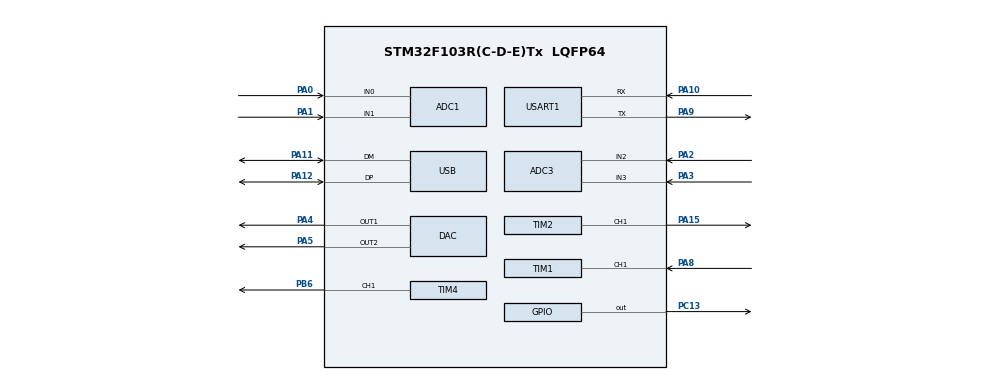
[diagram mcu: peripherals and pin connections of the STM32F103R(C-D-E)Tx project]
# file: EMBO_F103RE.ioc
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ADC1.AWD1ITMode=ENABLE
ADC1.Channel-6\#ChannelRegularConversion=ADC_CHANNEL_VREFINT
ADC1.Channel-7\#ChannelRegularConversion=ADC_CHANNEL_0
ADC1.Channel-8\#ChannelRegularConversion=ADC_CHANNEL_1
ADC1.EnableAnalogWatchDog=true
ADC1.ExternalTrigConv=ADC_EXTERNALTRIGCONV_T8_TRGO
ADC1.NbrOfConversion=3
ADC1.NbrOfConversionFlag=1
ADC1.Rank-6\#ChannelRegularConversion=1
ADC1.Rank-7\#ChannelRegularConversion=2
ADC1.Rank-8\#ChannelRegularConversion=3
ADC1.SamplingTime-6\#ChannelRegularConversion=ADC_SAMPLETIME_1CYCLE_5
ADC1.SamplingTime-7\#ChannelRegularConversion=ADC_SAMPLETIME_1CYCLE_5
ADC1.SamplingTime-8\#ChannelRegularConversion=ADC_SAMPLETIME_1CYCLE_5
ADC1.master=1
ADC3.AWD1ITMode=ENABLE
ADC3.Channel-0\#ChannelRegularConversion=ADC_CHANNEL_2
ADC3.Channel-1\#ChannelRegularConversion=ADC_CHANNEL_2
ADC3.EnableAnalogWatchDog=true
ADC3.ExternalTrigConv=ADC_EXTERNALTRIGCONV_T8_TRGO
ADC3.NbrOfConversion=2
ADC3.NbrOfConversionFlag=1
ADC3.Rank-0\#ChannelRegularConversion=1
ADC3.Rank-1\#ChannelRegularConversion=2
ADC3.SamplingTime-0\#ChannelRegularConversion=ADC_SAMPLETIME_1CYCLE_5
ADC3.SamplingTime-1\#ChannelRegularConversion=ADC_SAMPLETIME_1CYCLE_5
ADC3.WatchdogChannel=ADC_CHANNEL_2
DAC.DAC_Trigger=DAC_TRIGGER_T6_TRGO
DAC.DAC_Trigger2=DAC_TRIGGER_T7_TRGO
Dma.ADC1.2.Direction=DMA_PERIPH_TO_MEMORY
Dma.ADC1.2.Instance=DMA1_Channel1
Dma.ADC1.2.MemDataAlignment=DMA_MDATAALIGN_HALFWORD
Dma.ADC1.2.MemInc=DMA_MINC_ENABLE
Dma.ADC1.2.Mode=DMA_CIRCULAR
Dma.ADC1.2.PeriphDataAlignment=DMA_PDATAALIGN_HALFWORD
Dma.ADC1.2.PeriphInc=DMA_PINC_DISABLE
Dma.ADC1.2.Priority=DMA_PRIORITY_VERY_HIGH
Dma.ADC3.5.Direction=DMA_PERIPH_TO_MEMORY
Dma.ADC3.5.Instance=DMA2_Channel5
Dma.ADC3.5.MemDataAlignment=DMA_MDATAALIGN_HALFWORD
Dma.ADC3.5.MemInc=DMA_MINC_ENABLE
Dma.ADC3.5.Mode=DMA_CIRCULAR
Dma.ADC3.5.PeriphDataAlignment=DMA_PDATAALIGN_HALFWORD
Dma.ADC3.5.PeriphInc=DMA_PINC_DISABLE
Dma.ADC3.5.Priority=DMA_PRIORITY_VERY_HIGH
Dma.DAC_CH1.3.Direction=DMA_MEMORY_TO_PERIPH
Dma.DAC_CH1.3.Instance=DMA2_Channel3
Dma.DAC_CH1.3.MemDataAlignment=DMA_MDATAALIGN_WORD
Dma.DAC_CH1.3.MemInc=DMA_MINC_ENABLE
Dma.DAC_CH1.3.Mode=DMA_CIRCULAR
Dma.DAC_CH1.3.PeriphDataAlignment=DMA_PDATAALIGN_WORD
Dma.DAC_CH1.3.PeriphInc=DMA_PINC_DISABLE
Dma.DAC_CH1.3.Priority=DMA_PRIORITY_MEDIUM
Dma.DAC_CH2.4.Direction=DMA_MEMORY_TO_PERIPH
Dma.DAC_CH2.4.Instance=DMA2_Channel4
Dma.DAC_CH2.4.MemDataAlignment=DMA_MDATAALIGN_WORD
Dma.DAC_CH2.4.MemInc=DMA_MINC_ENABLE
Dma.DAC_CH2.4.Mode=DMA_CIRCULAR
Dma.DAC_CH2.4.PeriphDataAlignment=DMA_PDATAALIGN_WORD
Dma.DAC_CH2.4.PeriphInc=DMA_PINC_DISABLE
Dma.DAC_CH2.4.Priority=DMA_PRIORITY_MEDIUM
Dma.Request0=TIM1_CH1
Dma.Request1=TIM1_CH2
Dma.Request2=ADC1
Dma.Request3=DAC_CH1
Dma.Request4=DAC_CH2
Dma.Request5=ADC3
Dma.Request6=TIM8_CH3/UP
Dma.TIM1_CH1.0.Direction=DMA_PERIPH_TO_MEMORY
Dma.TIM1_CH1.0.Instance=DMA1_Channel2
Dma.TIM1_CH1.0.MemDataAlignment=DMA_MDATAALIGN_HALFWORD
Dma.TIM1_CH1.0.MemInc=DMA_MINC_ENABLE
Dma.TIM1_CH1.0.Mode=DMA_NORMAL
Dma.TIM1_CH1.0.PeriphDataAlignment=DMA_PDATAALIGN_HALFWORD
Dma.TIM1_CH1.0.PeriphInc=DMA_PINC_DISABLE
Dma.TIM1_CH1.0.Priority=DMA_PRIORITY_HIGH
Dma.TIM1_CH2.1.Direction=DMA_PERIPH_TO_MEMORY
Dma.TIM1_CH2.1.Instance=DMA1_Channel3
Dma.TIM1_CH2.1.MemDataAlignment=DMA_MDATAALIGN_HALFWORD
Dma.TIM1_CH2.1.MemInc=DMA_MINC_ENABLE
Dma.TIM1_CH2.1.Mode=DMA_NORMAL
Dma.TIM1_CH2.1.PeriphDataAlignment=DMA_PDATAALIGN_HALFWORD
Dma.TIM1_CH2.1.PeriphInc=DMA_PINC_DISABLE
Dma.TIM1_CH2.1.Priority=DMA_PRIORITY_HIGH
Dma.TIM8_CH3/UP.6.Direction=DMA_PERIPH_TO_MEMORY
Dma.TIM8_CH3/UP.6.Instance=DMA2_Channel1
Dma.TIM8_CH3/UP.6.MemDataAlignment=DMA_MDATAALIGN_BYTE
Dma.TIM8_CH3/UP.6.MemInc=DMA_MINC_ENABLE
Dma.TIM8_CH3/UP.6.Mode=DMA_CIRCULAR
Dma.TIM8_CH3/UP.6.PeriphDataAlignment=DMA_PDATAALIGN_BYTE
Dma.TIM8_CH3/UP.6.PeriphInc=DMA_PINC_DISABLE
Dma.TIM8_CH3/UP.6.Priority=DMA_PRIORITY_VERY_HIGH
Mcu.Family=STM32F1
Mcu.Name=STM32F103R(C-D-E)Tx
Mcu.Package=LQFP64
NVIC.PriorityGroup=NVIC_PRIORITYGROUP_4
NVIC.USB_LP_CAN1_RX0_IRQn=true\:7\:0\:true\:false\:true\:false\:true
PA0-WKUP.Signal=ADCx_IN0
PA1.Signal=ADCx_IN1
PA10.Mode=Asynchronous
PA10.Signal=USART1_RX
PA11.Mode=Device
PA11.Signal=USB_DM
PA12.Mode=Device
PA12.Signal=USB_DP
PA13.Mode=Trace_Asynchronous_SW
PA13.Signal=SYS_JTMS-SWDIO
PA14.Mode=Trace_Asynchronous_SW
PA14.Signal=SYS_JTCK-SWCLK
PA15.Signal=S_TIM2_CH1_ETR
PA2.Signal=ADCx_IN2
PA3.Signal=ADCx_IN3
PA4.Signal=COMP_DAC1_group
PA5.Signal=COMP_DAC2_group
PA8.Signal=S_TIM1_CH1
PA9.Mode=Asynchronous
PA9.Signal=USART1_TX
PB3.Mode=Trace_Asynchronous_SW
PB3.Signal=SYS_JTDO-TRACESWO
PB6.Signal=S_TIM4_CH1
PC13-TAMPER-RTC.PinState=GPIO_PIN_SET
PC13-TAMPER-RTC.Signal=GPIO_Output
PD0-OSC_IN.Mode=HSE-External-Oscillator
PD0-OSC_IN.Signal=RCC_OSC_IN
PD1-OSC_OUT.Mode=HSE-External-Oscillator
PD1-OSC_OUT.Signal=RCC_OSC_OUT
ProjectManager.HeapSize=0x0
ProjectManager.StackSize=0x400
ProjectManager.TargetToolchain=STM32CubeIDE
RCC.ADCPresc=RCC_ADCPCLK2_DIV6
RCC.AHBFreq_Value=72000000
RCC.APB1CLKDivider=RCC_HCLK_DIV2
RCC.APB1Freq_Value=36000000
RCC.APB1TimFreq_Value=72000000
RCC.APB2Freq_Value=72000000
RCC.APB2TimFreq_Value=72000000
RCC.HCLKFreq_Value=72000000
RCC.PLLMUL=RCC_PLL_MUL9
RCC.SYSCLKFreq_VALUE=72000000
RCC.SYSCLKSource=RCC_SYSCLKSOURCE_PLLCLK
RCC.USBFreq_Value=48000000
RCC.USBPrescaler=RCC_USBCLKSOURCE_PLL_DIV1_5
SH.ADCx_IN0.0=ADC1_IN0,IN0
SH.ADCx_IN1.0=ADC1_IN1,IN1
SH.ADCx_IN2.0=ADC3_IN2,IN2
SH.ADCx_IN3.0=ADC3_IN3,IN3
SH.COMP_DAC1_group.0=DAC_OUT1,DAC_OUT1
SH.COMP_DAC2_group.0=DAC_OUT2,DAC_OUT2
SH.S_TIM1_CH1.0=TIM1_CH1,Input_Capture1_from_TI1
SH.S_TIM1_CH1.1=TIM1_CH1,Input_Capture2_from_TI1
SH.S_TIM2_CH1_ETR.0=TIM2_CH1,PWM Generation1 CH1
SH.S_TIM4_CH1.0=TIM4_CH1,PWM Generation1 CH1
TIM1.Channel-Input_Capture1_from_TI1=TIM_CHANNEL_1
TIM1.Channel-Input_Capture2_from_TI1=TIM_CHANNEL_2
TIM1.Channel-Output\ Compare3\ No\ Output=TIM_CHANNEL_3
TIM2.Channel-PWM\ Generation1\ CH1=TIM_CHANNEL_1
TIM2.OCFastMode_PWM-PWM\ Generation1\ CH1=TIM_OCFAST_ENABLE
TIM2.Period=1000
TIM2.TIM_MasterOutputTrigger=TIM_TRGO_ENABLE
TIM2.TIM_MasterSlaveMode=TIM_MASTERSLAVEMODE_ENABLE
TIM4.AutoReloadPreload=TIM_AUTORELOAD_PRELOAD_ENABLE
TIM4.Channel-PWM\ Generation1\ CH1=TIM_CHANNEL_1
TIM4.OCFastMode_PWM-PWM\ Generation1\ CH1=TIM_OCFAST_ENABLE
TIM4.Period=72
TIM4.Prescaler=1000
TIM4.TIM_MasterOutputTrigger=TIM_TRGO_UPDATE
TIM6.TIM_MasterOutputTrigger=TIM_TRGO_UPDATE
TIM7.TIM_MasterOutputTrigger=TIM_TRGO_UPDATE
TIM8.Channel-Output\ Compare3\ No\ Output=TIM_CHANNEL_3
TIM8.TIM_MasterOutputTrigger=TIM_TRGO_UPDATE
USART1.VirtualMode=VM_ASYNC
USB_DEVICE.CLASS_NAME_FS=CDC
USB_DEVICE.MANUFACTURER_STRING=CTU/Jakub Parez
USB_DEVICE.PRODUCT_STRING_CDC_FS=EMBO
USB_DEVICE.VirtualMode=Cdc
USB_DEVICE.VirtualModeFS=Cdc_FS
VP_ADC1_Vref_Input.Mode=IN-Vrefint
VP_TIM1_VS_ClockSourceINT.Mode=Internal
VP_TIM1_VS_no_output3.Mode=Output Compare3 No Output
VP_TIM2_VS_ClockSourceINT.Mode=Internal
VP_TIM4_VS_ClockSourceINT.Mode=Internal
VP_TIM4_VS_ClockSourceITR.Mode=TriggerSource_ITR1
VP_TIM4_VS_ControllerModeTrigger.Mode=Trigger Mode
VP_TIM6_VS_ClockSourceINT.Mode=Enable_Timer
VP_TIM7_VS_ClockSourceINT.Mode=Enable_Timer
VP_TIM8_VS_ClockSourceINT.Mode=Internal
VP_TIM8_VS_no_output3.Mode=Output Compare3 No Output
VP_USB_DEVICE_VS_USB_DEVICE_CDC_FS.Mode=CDC_FS
board=custom

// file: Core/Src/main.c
/* USER CODE BEGIN Header */
/**
  ******************************************************************************
  * @file           : main.c
  * @brief          : Main program body
  ******************************************************************************
  * @attention
  *
  * <h2><center>&copy; Copyright (c) 2021 STMicroelectronics.
  * All rights reserved.</center></h2>
  *
  * This software component is licensed by ST under BSD 3-Clause license,
  * the "License"; You may not use this file except in compliance with the
  * License. You may obtain a copy of the License at:
  *                        opensource.org/licenses/BSD-3-Clause
  *
  ******************************************************************************
  */
/* USER CODE END Header */
#include "main.h"
#include "usb_device.h"

/* USER CODE BEGIN Includes */
#include "app.h"
/* USER CODE END Includes */

void SystemClock_Config(void);
static void MX_GPIO_Init(void);
static void MX_DMA_Init(void);
static void MX_TIM1_Init(void);
static void MX_USART1_UART_Init(void);
static void MX_ADC1_Init(void);
static void MX_DAC_Init(void);
static void MX_TIM2_Init(void);
static void MX_TIM4_Init(void);
static void MX_TIM6_Init(void);
static void MX_TIM7_Init(void);
static void MX_ADC3_Init(void);
static void MX_TIM8_Init(void);

int main(void)
{
  __disable_irq();

  /* MCU Configuration--------------------------------------------------------*/

  /* Reset of all peripherals, Initializes the Flash interface and the Systick. */
  HAL_Init();

  /* Configure the system clock */
  SystemClock_Config();

  /* Initialize all configured peripherals */
  MX_GPIO_Init();
  MX_DMA_Init();
  MX_TIM1_Init();
  MX_USART1_UART_Init();
  MX_ADC1_Init();
  MX_DAC_Init();
  MX_TIM2_Init();
  MX_TIM4_Init();
  MX_TIM6_Init();
  MX_USB_DEVICE_Init();
  MX_TIM7_Init();
  MX_ADC3_Init();
  MX_TIM8_Init();

  /* Infinite loop */
  /* USER CODE BEGIN WHILE */
  app_main();
    /* USER CODE END WHILE */

}

void SystemClock_Config(void)
{
  LL_FLASH_SetLatency(LL_FLASH_LATENCY_2);
  while(LL_FLASH_GetLatency()!= LL_FLASH_LATENCY_2)
  {
  }
  LL_RCC_HSE_Enable();

   /* Wait till HSE is ready */
  while(LL_RCC_HSE_IsReady() != 1)
  {

  }
  LL_RCC_PLL_ConfigDomain_SYS(LL_RCC_PLLSOURCE_HSE_DIV_1, LL_RCC_PLL_MUL_9);
  LL_RCC_PLL_Enable();

   /* Wait till PLL is ready */
  while(LL_RCC_PLL_IsReady() != 1)
  {

  }
  LL_RCC_SetAHBPrescaler(LL_RCC_SYSCLK_DIV_1);
  LL_RCC_SetAPB1Prescaler(LL_RCC_APB1_DIV_2);
  LL_RCC_SetAPB2Prescaler(LL_RCC_APB2_DIV_1);
  LL_RCC_SetSysClkSource(LL_RCC_SYS_CLKSOURCE_PLL);

   /* Wait till System clock is ready */
  while(LL_RCC_GetSysClkSource() != LL_RCC_SYS_CLKSOURCE_STATUS_PLL)
  {

  }
  LL_SetSystemCoreClock(72000000);

   /* Update the time base */
  if (HAL_InitTick (TICK_INT_PRIORITY) != HAL_OK)
  {
    Error_Handler();
  }
  LL_RCC_SetADCClockSource(LL_RCC_ADC_CLKSRC_PCLK2_DIV_6);
  LL_RCC_SetUSBClockSource(LL_RCC_USB_CLKSOURCE_PLL_DIV_1_5);
}

static void MX_ADC1_Init(void)
{

  LL_ADC_InitTypeDef ADC_InitStruct = {0};
  LL_ADC_CommonInitTypeDef ADC_CommonInitStruct = {0};
  LL_ADC_REG_InitTypeDef ADC_REG_InitStruct = {0};

  LL_GPIO_InitTypeDef GPIO_InitStruct = {0};

  /* Peripheral clock enable */
  LL_APB2_GRP1_EnableClock(LL_APB2_GRP1_PERIPH_ADC1);

  LL_APB2_GRP1_EnableClock(LL_APB2_GRP1_PERIPH_GPIOA);
  /**ADC1 GPIO Configuration
  PA0-WKUP   ------> ADC1_IN0
  PA1   ------> ADC1_IN1
  */
  GPIO_InitStruct.Pin = LL_GPIO_PIN_0|LL_GPIO_PIN_1;
  GPIO_InitStruct.Mode = LL_GPIO_MODE_ANALOG;
  LL_GPIO_Init(GPIOA, &GPIO_InitStruct);

  /* ADC1 DMA Init */

  /* ADC1 Init */
  LL_DMA_SetDataTransferDirection(DMA1, LL_DMA_CHANNEL_1, LL_DMA_DIRECTION_PERIPH_TO_MEMORY);

  LL_DMA_SetChannelPriorityLevel(DMA1, LL_DMA_CHANNEL_1, LL_DMA_PRIORITY_VERYHIGH);

  LL_DMA_SetMode(DMA1, LL_DMA_CHANNEL_1, LL_DMA_MODE_CIRCULAR);

  LL_DMA_SetPeriphIncMode(DMA1, LL_DMA_CHANNEL_1, LL_DMA_PERIPH_NOINCREMENT);

  LL_DMA_SetMemoryIncMode(DMA1, LL_DMA_CHANNEL_1, LL_DMA_MEMORY_INCREMENT);

  LL_DMA_SetPeriphSize(DMA1, LL_DMA_CHANNEL_1, LL_DMA_PDATAALIGN_HALFWORD);

  LL_DMA_SetMemorySize(DMA1, LL_DMA_CHANNEL_1, LL_DMA_MDATAALIGN_HALFWORD);

  /** Common config
  */
  ADC_InitStruct.DataAlignment = LL_ADC_DATA_ALIGN_RIGHT;
  ADC_InitStruct.SequencersScanMode = LL_ADC_SEQ_SCAN_ENABLE;
  LL_ADC_Init(ADC1, &ADC_InitStruct);
  ADC_CommonInitStruct.Multimode = LL_ADC_MULTI_INDEPENDENT;
  LL_ADC_CommonInit(__LL_ADC_COMMON_INSTANCE(ADC1), &ADC_CommonInitStruct);
  ADC_REG_InitStruct.TriggerSource = LL_ADC_REG_TRIG_EXT_TIM8_TRGO;
  ADC_REG_InitStruct.SequencerLength = LL_ADC_REG_SEQ_SCAN_ENABLE_3RANKS;
  ADC_REG_InitStruct.SequencerDiscont = LL_ADC_REG_SEQ_DISCONT_DISABLE;
  ADC_REG_InitStruct.ContinuousMode = LL_ADC_REG_CONV_SINGLE;
  ADC_REG_InitStruct.DMATransfer = LL_ADC_REG_DMA_TRANSFER_UNLIMITED;
  LL_ADC_REG_Init(ADC1, &ADC_REG_InitStruct);
  /** Configure Analog WatchDog
  */
  LL_ADC_SetAnalogWDMonitChannels(ADC1, LL_ADC_AWD_CHANNEL_0_REG);
  LL_ADC_SetAnalogWDThresholds(ADC1, LL_ADC_AWD_THRESHOLD_HIGH, 0);
  LL_ADC_SetAnalogWDThresholds(ADC1, LL_ADC_AWD_THRESHOLD_LOW, 0);
  LL_ADC_EnableIT_AWD1(ADC1);
  /** Configure Regular Channel
  */
  LL_ADC_REG_SetSequencerRanks(ADC1, LL_ADC_REG_RANK_1, LL_ADC_CHANNEL_VREFINT);
  LL_ADC_SetChannelSamplingTime(ADC1, LL_ADC_CHANNEL_VREFINT, LL_ADC_SAMPLINGTIME_1CYCLE_5);
  LL_ADC_SetCommonPathInternalCh(__LL_ADC_COMMON_INSTANCE(ADC1), LL_ADC_PATH_INTERNAL_VREFINT);
  /** Configure Regular Channel
  */
  LL_ADC_REG_SetSequencerRanks(ADC1, LL_ADC_REG_RANK_2, LL_ADC_CHANNEL_0);
  LL_ADC_SetChannelSamplingTime(ADC1, LL_ADC_CHANNEL_0, LL_ADC_SAMPLINGTIME_1CYCLE_5);
  /** Configure Regular Channel
  */
  LL_ADC_REG_SetSequencerRanks(ADC1, LL_ADC_REG_RANK_3, LL_ADC_CHANNEL_1);
  LL_ADC_SetChannelSamplingTime(ADC1, LL_ADC_CHANNEL_1, LL_ADC_SAMPLINGTIME_1CYCLE_5);

}

static void MX_ADC3_Init(void)
{

  /* USER CODE BEGIN ADC3_Init 0 */
  LL_ADC_REG_InitTypeDef ADC_REG_InitStruct = {0};
  /* USER CODE END ADC3_Init 0 */

  LL_ADC_InitTypeDef ADC_InitStruct = {0};

  LL_GPIO_InitTypeDef GPIO_InitStruct = {0};

  /* Peripheral clock enable */
  LL_APB2_GRP1_EnableClock(LL_APB2_GRP1_PERIPH_ADC3);

  LL_APB2_GRP1_EnableClock(LL_APB2_GRP1_PERIPH_GPIOA);
  /**ADC3 GPIO Configuration
  PA2   ------> ADC3_IN2
  PA3   ------> ADC3_IN3
  */
  GPIO_InitStruct.Pin = LL_GPIO_PIN_2|LL_GPIO_PIN_3;
  GPIO_InitStruct.Mode = LL_GPIO_MODE_ANALOG;
  LL_GPIO_Init(GPIOA, &GPIO_InitStruct);

  /* ADC3 DMA Init */

  /* ADC3 Init */
  LL_DMA_SetDataTransferDirection(DMA2, LL_DMA_CHANNEL_5, LL_DMA_DIRECTION_PERIPH_TO_MEMORY);

  LL_DMA_SetChannelPriorityLevel(DMA2, LL_DMA_CHANNEL_5, LL_DMA_PRIORITY_VERYHIGH);

  LL_DMA_SetMode(DMA2, LL_DMA_CHANNEL_5, LL_DMA_MODE_CIRCULAR);

  LL_DMA_SetPeriphIncMode(DMA2, LL_DMA_CHANNEL_5, LL_DMA_PERIPH_NOINCREMENT);

  LL_DMA_SetMemoryIncMode(DMA2, LL_DMA_CHANNEL_5, LL_DMA_MEMORY_INCREMENT);

  LL_DMA_SetPeriphSize(DMA2, LL_DMA_CHANNEL_5, LL_DMA_PDATAALIGN_HALFWORD);

  LL_DMA_SetMemorySize(DMA2, LL_DMA_CHANNEL_5, LL_DMA_MDATAALIGN_HALFWORD);

  /** Common config
  */
  ADC_InitStruct.DataAlignment = LL_ADC_DATA_ALIGN_RIGHT;
  ADC_InitStruct.SequencersScanMode = LL_ADC_SEQ_SCAN_ENABLE;
  LL_ADC_Init(ADC3, &ADC_InitStruct);
  /** Configure Analog WatchDog
  */
  LL_ADC_SetAnalogWDMonitChannels(ADC3, LL_ADC_AWD_CHANNEL_2_REG);
  LL_ADC_SetAnalogWDThresholds(ADC3, LL_ADC_AWD_THRESHOLD_HIGH, 0);
  LL_ADC_SetAnalogWDThresholds(ADC3, LL_ADC_AWD_THRESHOLD_LOW, 0);
  LL_ADC_EnableIT_AWD1(ADC3);
  /** Configure Regular Channel
  */
  LL_ADC_REG_SetSequencerRanks(ADC3, LL_ADC_REG_RANK_1, LL_ADC_CHANNEL_2);
  LL_ADC_SetChannelSamplingTime(ADC3, LL_ADC_CHANNEL_2, LL_ADC_SAMPLINGTIME_1CYCLE_5);
  /** Configure Regular Channel
  */
  LL_ADC_REG_SetSequencerRanks(ADC3, LL_ADC_REG_RANK_2, LL_ADC_CHANNEL_2);
  LL_ADC_SetChannelSamplingTime(ADC3, LL_ADC_CHANNEL_2, LL_ADC_SAMPLINGTIME_1CYCLE_5);
  /* USER CODE BEGIN ADC3_Init 2 */

  ADC_REG_InitStruct.TriggerSource = LL_ADC_REG_TRIG_EXT_TIM8_TRGO_ADC3;
  ADC_REG_InitStruct.SequencerLength = LL_ADC_REG_SEQ_SCAN_ENABLE_2RANKS;
  ADC_REG_InitStruct.SequencerDiscont = LL_ADC_REG_SEQ_DISCONT_DISABLE;
  ADC_REG_InitStruct.ContinuousMode = LL_ADC_REG_CONV_SINGLE;
  ADC_REG_InitStruct.DMATransfer = LL_ADC_REG_DMA_TRANSFER_UNLIMITED;
  LL_ADC_REG_Init(ADC3, &ADC_REG_InitStruct);

  /* USER CODE END ADC3_Init 2 */

}

static void MX_DAC_Init(void)
{

  LL_DAC_InitTypeDef DAC_InitStruct = {0};

  LL_GPIO_InitTypeDef GPIO_InitStruct = {0};

  /* Peripheral clock enable */
  LL_APB1_GRP1_EnableClock(LL_APB1_GRP1_PERIPH_DAC1);

  LL_APB2_GRP1_EnableClock(LL_APB2_GRP1_PERIPH_GPIOA);
  /**DAC GPIO Configuration
  PA4   ------> DAC_OUT1
  PA5   ------> DAC_OUT2
  */
  GPIO_InitStruct.Pin = LL_GPIO_PIN_4|LL_GPIO_PIN_5;
  GPIO_InitStruct.Mode = LL_GPIO_MODE_ANALOG;
  LL_GPIO_Init(GPIOA, &GPIO_InitStruct);

  /* DAC DMA Init */

  /* DAC_CH1 Init */
  LL_DMA_SetDataTransferDirection(DMA2, LL_DMA_CHANNEL_3, LL_DMA_DIRECTION_MEMORY_TO_PERIPH);

  LL_DMA_SetChannelPriorityLevel(DMA2, LL_DMA_CHANNEL_3, LL_DMA_PRIORITY_MEDIUM);

  LL_DMA_SetMode(DMA2, LL_DMA_CHANNEL_3, LL_DMA_MODE_CIRCULAR);

  LL_DMA_SetPeriphIncMode(DMA2, LL_DMA_CHANNEL_3, LL_DMA_PERIPH_NOINCREMENT);

  LL_DMA_SetMemoryIncMode(DMA2, LL_DMA_CHANNEL_3, LL_DMA_MEMORY_INCREMENT);

  LL_DMA_SetPeriphSize(DMA2, LL_DMA_CHANNEL_3, LL_DMA_PDATAALIGN_WORD);

  LL_DMA_SetMemorySize(DMA2, LL_DMA_CHANNEL_3, LL_DMA_MDATAALIGN_WORD);

  /* DAC_CH2 Init */
  LL_DMA_SetDataTransferDirection(DMA2, LL_DMA_CHANNEL_4, LL_DMA_DIRECTION_MEMORY_TO_PERIPH);

  LL_DMA_SetChannelPriorityLevel(DMA2, LL_DMA_CHANNEL_4, LL_DMA_PRIORITY_MEDIUM);

  LL_DMA_SetMode(DMA2, LL_DMA_CHANNEL_4, LL_DMA_MODE_CIRCULAR);

  LL_DMA_SetPeriphIncMode(DMA2, LL_DMA_CHANNEL_4, LL_DMA_PERIPH_NOINCREMENT);

  LL_DMA_SetMemoryIncMode(DMA2, LL_DMA_CHANNEL_4, LL_DMA_MEMORY_INCREMENT);

  LL_DMA_SetPeriphSize(DMA2, LL_DMA_CHANNEL_4, LL_DMA_PDATAALIGN_WORD);

  LL_DMA_SetMemorySize(DMA2, LL_DMA_CHANNEL_4, LL_DMA_MDATAALIGN_WORD);

  /** DAC channel OUT1 config
  */
  DAC_InitStruct.TriggerSource = LL_DAC_TRIG_EXT_TIM6_TRGO;
  DAC_InitStruct.WaveAutoGeneration = LL_DAC_WAVE_AUTO_GENERATION_NONE;
  DAC_InitStruct.OutputBuffer = LL_DAC_OUTPUT_BUFFER_ENABLE;
  LL_DAC_Init(DAC, LL_DAC_CHANNEL_1, &DAC_InitStruct);
  LL_DAC_EnableTrigger(DAC, LL_DAC_CHANNEL_1);
  /** DAC channel OUT2 config
  */
  DAC_InitStruct.TriggerSource = LL_DAC_TRIG_EXT_TIM7_TRGO;
  LL_DAC_Init(DAC, LL_DAC_CHANNEL_2, &DAC_InitStruct);
  LL_DAC_EnableTrigger(DAC, LL_DAC_CHANNEL_2);

}

static void MX_TIM1_Init(void)
{

  LL_TIM_InitTypeDef TIM_InitStruct = {0};
  LL_TIM_OC_InitTypeDef TIM_OC_InitStruct = {0};
  LL_TIM_BDTR_InitTypeDef TIM_BDTRInitStruct = {0};

  LL_GPIO_InitTypeDef GPIO_InitStruct = {0};

  /* Peripheral clock enable */
  LL_APB2_GRP1_EnableClock(LL_APB2_GRP1_PERIPH_TIM1);

  LL_APB2_GRP1_EnableClock(LL_APB2_GRP1_PERIPH_GPIOA);
  /**TIM1 GPIO Configuration
  PA8   ------> TIM1_CH1
  */
  GPIO_InitStruct.Pin = LL_GPIO_PIN_8;
  GPIO_InitStruct.Mode = LL_GPIO_MODE_FLOATING;
  LL_GPIO_Init(GPIOA, &GPIO_InitStruct);

  /* TIM1 DMA Init */

  /* TIM1_CH1 Init */
  LL_DMA_SetDataTransferDirection(DMA1, LL_DMA_CHANNEL_2, LL_DMA_DIRECTION_PERIPH_TO_MEMORY);

  LL_DMA_SetChannelPriorityLevel(DMA1, LL_DMA_CHANNEL_2, LL_DMA_PRIORITY_HIGH);

  LL_DMA_SetMode(DMA1, LL_DMA_CHANNEL_2, LL_DMA_MODE_NORMAL);

  LL_DMA_SetPeriphIncMode(DMA1, LL_DMA_CHANNEL_2, LL_DMA_PERIPH_NOINCREMENT);

  LL_DMA_SetMemoryIncMode(DMA1, LL_DMA_CHANNEL_2, LL_DMA_MEMORY_INCREMENT);

  LL_DMA_SetPeriphSize(DMA1, LL_DMA_CHANNEL_2, LL_DMA_PDATAALIGN_HALFWORD);

  LL_DMA_SetMemorySize(DMA1, LL_DMA_CHANNEL_2, LL_DMA_MDATAALIGN_HALFWORD);

  /* TIM1_CH2 Init */
  LL_DMA_SetDataTransferDirection(DMA1, LL_DMA_CHANNEL_3, LL_DMA_DIRECTION_PERIPH_TO_MEMORY);

  LL_DMA_SetChannelPriorityLevel(DMA1, LL_DMA_CHANNEL_3, LL_DMA_PRIORITY_HIGH);

  LL_DMA_SetMode(DMA1, LL_DMA_CHANNEL_3, LL_DMA_MODE_NORMAL);

  LL_DMA_SetPeriphIncMode(DMA1, LL_DMA_CHANNEL_3, LL_DMA_PERIPH_NOINCREMENT);

  LL_DMA_SetMemoryIncMode(DMA1, LL_DMA_CHANNEL_3, LL_DMA_MEMORY_INCREMENT);

  LL_DMA_SetPeriphSize(DMA1, LL_DMA_CHANNEL_3, LL_DMA_PDATAALIGN_HALFWORD);

  LL_DMA_SetMemorySize(DMA1, LL_DMA_CHANNEL_3, LL_DMA_MDATAALIGN_HALFWORD);

  TIM_InitStruct.Prescaler = 0;
  TIM_InitStruct.CounterMode = LL_TIM_COUNTERMODE_UP;
  TIM_InitStruct.Autoreload = 65535;
  TIM_InitStruct.ClockDivision = LL_TIM_CLOCKDIVISION_DIV1;
  TIM_InitStruct.RepetitionCounter = 0;
  LL_TIM_Init(TIM1, &TIM_InitStruct);
  LL_TIM_DisableARRPreload(TIM1);
  LL_TIM_SetClockSource(TIM1, LL_TIM_CLOCKSOURCE_INTERNAL);
  TIM_OC_InitStruct.OCMode = LL_TIM_OCMODE_FROZEN;
  TIM_OC_InitStruct.OCState = LL_TIM_OCSTATE_DISABLE;
  TIM_OC_InitStruct.OCNState = LL_TIM_OCSTATE_DISABLE;
  TIM_OC_InitStruct.CompareValue = 0;
  TIM_OC_InitStruct.OCPolarity = LL_TIM_OCPOLARITY_HIGH;
  TIM_OC_InitStruct.OCNPolarity = LL_TIM_OCPOLARITY_HIGH;
  TIM_OC_InitStruct.OCIdleState = LL_TIM_OCIDLESTATE_LOW;
  TIM_OC_InitStruct.OCNIdleState = LL_TIM_OCIDLESTATE_LOW;
  LL_TIM_OC_Init(TIM1, LL_TIM_CHANNEL_CH3, &TIM_OC_InitStruct);
  LL_TIM_OC_DisableFast(TIM1, LL_TIM_CHANNEL_CH3);
  LL_TIM_SetTriggerOutput(TIM1, LL_TIM_TRGO_RESET);
  LL_TIM_DisableMasterSlaveMode(TIM1);
  LL_TIM_IC_SetActiveInput(TIM1, LL_TIM_CHANNEL_CH1, LL_TIM_ACTIVEINPUT_DIRECTTI);
  LL_TIM_IC_SetPrescaler(TIM1, LL_TIM_CHANNEL_CH1, LL_TIM_ICPSC_DIV1);
  LL_TIM_IC_SetFilter(TIM1, LL_TIM_CHANNEL_CH1, LL_TIM_IC_FILTER_FDIV1);
  LL_TIM_IC_SetPolarity(TIM1, LL_TIM_CHANNEL_CH1, LL_TIM_IC_POLARITY_RISING);
  LL_TIM_IC_SetActiveInput(TIM1, LL_TIM_CHANNEL_CH2, LL_TIM_ACTIVEINPUT_INDIRECTTI);
  LL_TIM_IC_SetPrescaler(TIM1, LL_TIM_CHANNEL_CH2, LL_TIM_ICPSC_DIV1);
  LL_TIM_IC_SetFilter(TIM1, LL_TIM_CHANNEL_CH2, LL_TIM_IC_FILTER_FDIV1);
  LL_TIM_IC_SetPolarity(TIM1, LL_TIM_CHANNEL_CH2, LL_TIM_IC_POLARITY_RISING);
  TIM_BDTRInitStruct.OSSRState = LL_TIM_OSSR_DISABLE;
  TIM_BDTRInitStruct.OSSIState = LL_TIM_OSSI_DISABLE;
  TIM_BDTRInitStruct.LockLevel = LL_TIM_LOCKLEVEL_OFF;
  TIM_BDTRInitStruct.DeadTime = 0;
  TIM_BDTRInitStruct.BreakState = LL_TIM_BREAK_DISABLE;
  TIM_BDTRInitStruct.BreakPolarity = LL_TIM_BREAK_POLARITY_HIGH;
  TIM_BDTRInitStruct.AutomaticOutput = LL_TIM_AUTOMATICOUTPUT_DISABLE;
  LL_TIM_BDTR_Init(TIM1, &TIM_BDTRInitStruct);

}

static void MX_TIM2_Init(void)
{

  LL_TIM_InitTypeDef TIM_InitStruct = {0};
  LL_TIM_OC_InitTypeDef TIM_OC_InitStruct = {0};

  LL_GPIO_InitTypeDef GPIO_InitStruct = {0};

  /* Peripheral clock enable */
  LL_APB1_GRP1_EnableClock(LL_APB1_GRP1_PERIPH_TIM2);

  TIM_InitStruct.Prescaler = 0;
  TIM_InitStruct.CounterMode = LL_TIM_COUNTERMODE_UP;
  TIM_InitStruct.Autoreload = 1000;
  TIM_InitStruct.ClockDivision = LL_TIM_CLOCKDIVISION_DIV1;
  LL_TIM_Init(TIM2, &TIM_InitStruct);
  LL_TIM_DisableARRPreload(TIM2);
  LL_TIM_SetClockSource(TIM2, LL_TIM_CLOCKSOURCE_INTERNAL);
  LL_TIM_OC_EnablePreload(TIM2, LL_TIM_CHANNEL_CH1);
  TIM_OC_InitStruct.OCMode = LL_TIM_OCMODE_PWM1;
  TIM_OC_InitStruct.OCState = LL_TIM_OCSTATE_DISABLE;
  TIM_OC_InitStruct.OCNState = LL_TIM_OCSTATE_DISABLE;
  TIM_OC_InitStruct.CompareValue = 0;
  TIM_OC_InitStruct.OCPolarity = LL_TIM_OCPOLARITY_HIGH;
  LL_TIM_OC_Init(TIM2, LL_TIM_CHANNEL_CH1, &TIM_OC_InitStruct);
  LL_TIM_OC_EnableFast(TIM2, LL_TIM_CHANNEL_CH1);
  LL_TIM_SetTriggerOutput(TIM2, LL_TIM_TRGO_ENABLE);
  LL_TIM_EnableMasterSlaveMode(TIM2);
  LL_APB2_GRP1_EnableClock(LL_APB2_GRP1_PERIPH_GPIOA);
  /**TIM2 GPIO Configuration
  PA15   ------> TIM2_CH1
  */
  GPIO_InitStruct.Pin = LL_GPIO_PIN_15;
  GPIO_InitStruct.Mode = LL_GPIO_MODE_ALTERNATE;
  GPIO_InitStruct.Speed = LL_GPIO_SPEED_FREQ_LOW;
  GPIO_InitStruct.OutputType = LL_GPIO_OUTPUT_PUSHPULL;
  LL_GPIO_Init(GPIOA, &GPIO_InitStruct);

  LL_GPIO_AF_RemapPartial1_TIM2();

}

static void MX_TIM4_Init(void)
{

  LL_TIM_InitTypeDef TIM_InitStruct = {0};
  LL_TIM_OC_InitTypeDef TIM_OC_InitStruct = {0};

  LL_GPIO_InitTypeDef GPIO_InitStruct = {0};

  /* Peripheral clock enable */
  LL_APB1_GRP1_EnableClock(LL_APB1_GRP1_PERIPH_TIM4);

  TIM_InitStruct.Prescaler = 1000;
  TIM_InitStruct.CounterMode = LL_TIM_COUNTERMODE_UP;
  TIM_InitStruct.Autoreload = 72;
  TIM_InitStruct.ClockDivision = LL_TIM_CLOCKDIVISION_DIV1;
  LL_TIM_Init(TIM4, &TIM_InitStruct);
  LL_TIM_EnableARRPreload(TIM4);
  LL_TIM_SetClockSource(TIM4, LL_TIM_CLOCKSOURCE_INTERNAL);
  LL_TIM_OC_EnablePreload(TIM4, LL_TIM_CHANNEL_CH1);
  TIM_OC_InitStruct.OCMode = LL_TIM_OCMODE_PWM1;
  TIM_OC_InitStruct.OCState = LL_TIM_OCSTATE_DISABLE;
  TIM_OC_InitStruct.OCNState = LL_TIM_OCSTATE_DISABLE;
  TIM_OC_InitStruct.CompareValue = 0;
  TIM_OC_InitStruct.OCPolarity = LL_TIM_OCPOLARITY_HIGH;
  LL_TIM_OC_Init(TIM4, LL_TIM_CHANNEL_CH1, &TIM_OC_InitStruct);
  LL_TIM_OC_EnableFast(TIM4, LL_TIM_CHANNEL_CH1);
  LL_TIM_SetTriggerInput(TIM4, LL_TIM_TS_ITR1);
  LL_TIM_SetSlaveMode(TIM4, LL_TIM_SLAVEMODE_TRIGGER);
  LL_TIM_DisableIT_TRIG(TIM4);
  LL_TIM_DisableDMAReq_TRIG(TIM4);
  LL_TIM_SetTriggerOutput(TIM4, LL_TIM_TRGO_UPDATE);
  LL_TIM_DisableMasterSlaveMode(TIM4);
  LL_APB2_GRP1_EnableClock(LL_APB2_GRP1_PERIPH_GPIOB);
  /**TIM4 GPIO Configuration
  PB6   ------> TIM4_CH1
  */
  GPIO_InitStruct.Pin = LL_GPIO_PIN_6;
  GPIO_InitStruct.Mode = LL_GPIO_MODE_ALTERNATE;
  GPIO_InitStruct.Speed = LL_GPIO_SPEED_FREQ_LOW;
  GPIO_InitStruct.OutputType = LL_GPIO_OUTPUT_PUSHPULL;
  LL_GPIO_Init(GPIOB, &GPIO_InitStruct);

}

static void MX_TIM6_Init(void)
{

  LL_TIM_InitTypeDef TIM_InitStruct = {0};

  /* Peripheral clock enable */
  LL_APB1_GRP1_EnableClock(LL_APB1_GRP1_PERIPH_TIM6);

  TIM_InitStruct.Prescaler = 0;
  TIM_InitStruct.CounterMode = LL_TIM_COUNTERMODE_UP;
  TIM_InitStruct.Autoreload = 65535;
  LL_TIM_Init(TIM6, &TIM_InitStruct);
  LL_TIM_DisableARRPreload(TIM6);
  LL_TIM_SetTriggerOutput(TIM6, LL_TIM_TRGO_UPDATE);
  LL_TIM_DisableMasterSlaveMode(TIM6);

}

static void MX_TIM7_Init(void)
{

  LL_TIM_InitTypeDef TIM_InitStruct = {0};

  /* Peripheral clock enable */
  LL_APB1_GRP1_EnableClock(LL_APB1_GRP1_PERIPH_TIM7);

  TIM_InitStruct.Prescaler = 0;
  TIM_InitStruct.CounterMode = LL_TIM_COUNTERMODE_UP;
  TIM_InitStruct.Autoreload = 65535;
  LL_TIM_Init(TIM7, &TIM_InitStruct);
  LL_TIM_DisableARRPreload(TIM7);
  LL_TIM_SetTriggerOutput(TIM7, LL_TIM_TRGO_UPDATE);
  LL_TIM_DisableMasterSlaveMode(TIM7);

}

static void MX_TIM8_Init(void)
{

  LL_TIM_InitTypeDef TIM_InitStruct = {0};
  LL_TIM_OC_InitTypeDef TIM_OC_InitStruct = {0};
  LL_TIM_BDTR_InitTypeDef TIM_BDTRInitStruct = {0};

  /* Peripheral clock enable */
  LL_APB2_GRP1_EnableClock(LL_APB2_GRP1_PERIPH_TIM8);

  /* TIM8 DMA Init */

  /* TIM8_CH3_UP Init */
  LL_DMA_SetDataTransferDirection(DMA2, LL_DMA_CHANNEL_1, LL_DMA_DIRECTION_PERIPH_TO_MEMORY);

  LL_DMA_SetChannelPriorityLevel(DMA2, LL_DMA_CHANNEL_1, LL_DMA_PRIORITY_VERYHIGH);

  LL_DMA_SetMode(DMA2, LL_DMA_CHANNEL_1, LL_DMA_MODE_CIRCULAR);

  LL_DMA_SetPeriphIncMode(DMA2, LL_DMA_CHANNEL_1, LL_DMA_PERIPH_NOINCREMENT);

  LL_DMA_SetMemoryIncMode(DMA2, LL_DMA_CHANNEL_1, LL_DMA_MEMORY_INCREMENT);

  LL_DMA_SetPeriphSize(DMA2, LL_DMA_CHANNEL_1, LL_DMA_PDATAALIGN_BYTE);

  LL_DMA_SetMemorySize(DMA2, LL_DMA_CHANNEL_1, LL_DMA_MDATAALIGN_BYTE);

  TIM_InitStruct.Prescaler = 0;
  TIM_InitStruct.CounterMode = LL_TIM_COUNTERMODE_UP;
  TIM_InitStruct.Autoreload = 65535;
  TIM_InitStruct.ClockDivision = LL_TIM_CLOCKDIVISION_DIV1;
  TIM_InitStruct.RepetitionCounter = 0;
  LL_TIM_Init(TIM8, &TIM_InitStruct);
  LL_TIM_DisableARRPreload(TIM8);
  LL_TIM_SetClockSource(TIM8, LL_TIM_CLOCKSOURCE_INTERNAL);
  TIM_OC_InitStruct.OCMode = LL_TIM_OCMODE_FROZEN;
  TIM_OC_InitStruct.OCState = LL_TIM_OCSTATE_DISABLE;
  TIM_OC_InitStruct.OCNState = LL_TIM_OCSTATE_DISABLE;
  TIM_OC_InitStruct.CompareValue = 0;
  TIM_OC_InitStruct.OCPolarity = LL_TIM_OCPOLARITY_HIGH;
  TIM_OC_InitStruct.OCNPolarity = LL_TIM_OCPOLARITY_HIGH;
  TIM_OC_InitStruct.OCIdleState = LL_TIM_OCIDLESTATE_LOW;
  TIM_OC_InitStruct.OCNIdleState = LL_TIM_OCIDLESTATE_LOW;
  LL_TIM_OC_Init(TIM8, LL_TIM_CHANNEL_CH3, &TIM_OC_InitStruct);
  LL_TIM_OC_DisableFast(TIM8, LL_TIM_CHANNEL_CH3);
  LL_TIM_SetTriggerOutput(TIM8, LL_TIM_TRGO_UPDATE);
  LL_TIM_DisableMasterSlaveMode(TIM8);
  TIM_BDTRInitStruct.OSSRState = LL_TIM_OSSR_DISABLE;
  TIM_BDTRInitStruct.OSSIState = LL_TIM_OSSI_DISABLE;
  TIM_BDTRInitStruct.LockLevel = LL_TIM_LOCKLEVEL_OFF;
  TIM_BDTRInitStruct.DeadTime = 0;
  TIM_BDTRInitStruct.BreakState = LL_TIM_BREAK_DISABLE;
  TIM_BDTRInitStruct.BreakPolarity = LL_TIM_BREAK_POLARITY_HIGH;
  TIM_BDTRInitStruct.AutomaticOutput = LL_TIM_AUTOMATICOUTPUT_DISABLE;
  LL_TIM_BDTR_Init(TIM8, &TIM_BDTRInitStruct);

}

static void MX_USART1_UART_Init(void)
{

  LL_USART_InitTypeDef USART_InitStruct = {0};

  LL_GPIO_InitTypeDef GPIO_InitStruct = {0};

  /* Peripheral clock enable */
  LL_APB2_GRP1_EnableClock(LL_APB2_GRP1_PERIPH_USART1);

  LL_APB2_GRP1_EnableClock(LL_APB2_GRP1_PERIPH_GPIOA);
  /**USART1 GPIO Configuration
  PA9   ------> USART1_TX
  PA10   ------> USART1_RX
  */
  GPIO_InitStruct.Pin = LL_GPIO_PIN_9;
  GPIO_InitStruct.Mode = LL_GPIO_MODE_ALTERNATE;
  GPIO_InitStruct.Speed = LL_GPIO_SPEED_FREQ_HIGH;
  GPIO_InitStruct.OutputType = LL_GPIO_OUTPUT_PUSHPULL;
  LL_GPIO_Init(GPIOA, &GPIO_InitStruct);

  GPIO_InitStruct.Pin = LL_GPIO_PIN_10;
  GPIO_InitStruct.Mode = LL_GPIO_MODE_FLOATING;
  LL_GPIO_Init(GPIOA, &GPIO_InitStruct);

  USART_InitStruct.BaudRate = 115200;
  USART_InitStruct.DataWidth = LL_USART_DATAWIDTH_8B;
  USART_InitStruct.StopBits = LL_USART_STOPBITS_1;
  USART_InitStruct.Parity = LL_USART_PARITY_NONE;
  USART_InitStruct.TransferDirection = LL_USART_DIRECTION_TX_RX;
  USART_InitStruct.HardwareFlowControl = LL_USART_HWCONTROL_NONE;
  USART_InitStruct.OverSampling = LL_USART_OVERSAMPLING_16;
  LL_USART_Init(USART1, &USART_InitStruct);
  LL_USART_ConfigAsyncMode(USART1);
  LL_USART_Enable(USART1);

}

static void MX_DMA_Init(void)
{

  /* Init with LL driver */
  /* DMA controller clock enable */
  LL_AHB1_GRP1_EnableClock(LL_AHB1_GRP1_PERIPH_DMA1);
  LL_AHB1_GRP1_EnableClock(LL_AHB1_GRP1_PERIPH_DMA2);

}

static void MX_GPIO_Init(void)
{
  LL_GPIO_InitTypeDef GPIO_InitStruct = {0};

  /* GPIO Ports Clock Enable */
  LL_APB2_GRP1_EnableClock(LL_APB2_GRP1_PERIPH_GPIOC);
  LL_APB2_GRP1_EnableClock(LL_APB2_GRP1_PERIPH_GPIOD);
  LL_APB2_GRP1_EnableClock(LL_APB2_GRP1_PERIPH_GPIOA);
  LL_APB2_GRP1_EnableClock(LL_APB2_GRP1_PERIPH_GPIOB);

  /**/
  LL_GPIO_SetOutputPin(GPIOC, LL_GPIO_PIN_13);

  /**/
  GPIO_InitStruct.Pin = LL_GPIO_PIN_13;
  GPIO_InitStruct.Mode = LL_GPIO_MODE_OUTPUT;
  GPIO_InitStruct.Speed = LL_GPIO_SPEED_FREQ_LOW;
  GPIO_InitStruct.OutputType = LL_GPIO_OUTPUT_PUSHPULL;
  LL_GPIO_Init(GPIOC, &GPIO_InitStruct);

}

void Error_Handler(void)
{
}

/************************ (C) COPYRIGHT STMicroelectronics *****END OF FILE****/
